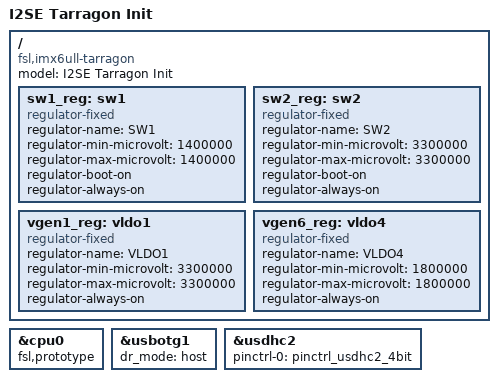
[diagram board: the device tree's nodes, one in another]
#include "imx6ull-tarragon-common.dtsi"

/ {
	model = "I2SE Tarragon Init";
	compatible = "fsl,imx6ull-tarragon", "fsl,imx6ull";

	/* Values take from PF3001 datasheet
	 * OTP configuration: A7
	 */
	sw1_reg: sw1 {
		compatible = "regulator-fixed";
		regulator-name = "SW1";
		regulator-min-microvolt = <1400000>;
		regulator-max-microvolt = <1400000>;
		regulator-boot-on;
		regulator-always-on;
	};

	sw2_reg: sw2 {
		compatible = "regulator-fixed";
		regulator-name = "SW2";
		regulator-min-microvolt = <3300000>;
		regulator-max-microvolt = <3300000>;
		regulator-boot-on;
		regulator-always-on;
	};

	vgen1_reg: vldo1 {
		compatible = "regulator-fixed";
		regulator-name = "VLDO1";
		regulator-min-microvolt = <3300000>;
		regulator-max-microvolt = <3300000>;
		regulator-always-on;
	};

	vgen6_reg: vldo4 {
		compatible = "regulator-fixed";
		regulator-name = "VLDO4";
		regulator-min-microvolt = <1800000>;
		regulator-max-microvolt = <1800000>;
		regulator-always-on;
	};
};

&cpu0 {
	fsl,prototype;
};

&usbotg1 {
	dr_mode = "host";
	status = "okay";
};

&usdhc2 {
	pinctrl-names = "default";
	pinctrl-0 = <&pinctrl_usdhc2_4bit>;
};
